# CPU_TPIU register map
Vendor: Texas Instruments
Peripheral module from a debugger description file (folder CC26x4).
Registers are 32-bit, read-only, reset 0x0 unless marked. A register's access mark holds for its fields unless they carry their own. Offsets are as the file gives them; lines under a group give offsets from that group; [hi:lo] are bit positions; {n}, {i} and the like mark numbered series; 'fields as' and 'values as' point back to an identical list; <NAME> marks a mode.

## CPU_TPIU — Cortex-M's Trace Port Interface Unit (TPIU)
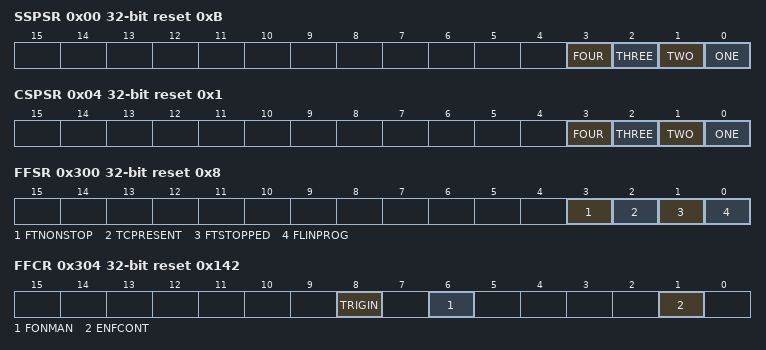
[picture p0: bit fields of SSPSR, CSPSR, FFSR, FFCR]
0x00 SSPSR reset 0xB — Supported Sync Port Sizes This register represents a single port size that is supported on the device, that is, 4, 2 or 1. This is to ensure that tools do not attempt to select a port width that an attached TPA cannot capture.
  [3] FOUR — 4-bit port size support 0x0: Not supported 0x1: Supported
  [2] THREE — 3-bit port size support 0x0: Not supported 0x1: Supported
  [1] TWO — 2-bit port size support 0x0: Not supported 0x1: Supported
  [0] ONE — 1-bit port size support 0x0: Not supported 0x1: Supported
0x04 CSPSR rw reset 0x1 — Current Sync Port Size This register has the same format as SSPSR but only one bit can be set, and all others must be zero. Writing values with more than one bit set, or setting a bit that is not indicated as supported can cause Unpredictable behavior. On reset this defaults to the smallest possible port size, 1 bit.
  [3] FOUR — 4-bit port enable Writing values with more than one bit set in CSPSR, or setting a bit that is not indicated as supported in SSPSR can cause Unpredictable behavior.
  [2] THREE — 3-bit port enable Writing values with more than one bit set in CSPSR, or setting a bit that is not indicated as supported in SSPSR can cause Unpredictable behavior.
  [1] TWO — 2-bit port enable Writing values with more than one bit set in CSPSR, or setting a bit that is not indicated as supported in SSPSR can cause Unpredictable behavior.
  [0] ONE — 1-bit port enable Writing values with more than one bit set in CSPSR, or setting a bit that is not indicated as supported in SSPSR can cause Unpredictable behavior.
0x10 ACPR rw — Async Clock Prescaler This register scales the baud rate of the asynchronous output.
  [12:0] PRESCALER — Divisor for input trace clock is (PRESCALER + 1).
0xF0 SPPR rw reset 0x1 — Selected Pin Protocol This register selects the protocol to be used for trace output. Note: If this register is changed while trace data is being output, data corruption occurs.
  [1:0] PROTOCOL — Trace output protocol
    2=SWO_NRZ (SerialWire Output (NRZ)); 1=SWO_MANCHESTER (SerialWire Output (Manchester). This is the reset value.); 0=TRACEPORT (TracePort mode)
0x300 FFSR reset 0x8 — Formatter and Flush Status
  [3] FTNONSTOP — 0: Formatter can be stopped 1: Formatter cannot be stopped
  [2] TCPRESENT — This field always reads as zero
  [1] FTSTOPPED — This field always reads as zero
  [0] FLINPROG — Read only. Flush in progress. Value can be: 0x0 When all the data received, before the flush is acknowledged, has been output on the trace port 0x1 When a flush is initiated.
0x304 FFCR rw reset 0x142 — Formatter and Flush Control When one of the two single wire output (SWO) modes is selected, ENFCONT enables the formatter to be bypassed. If the formatter is bypassed, only the ITM/DWT trace source (ATDATA2) passes through. The TPIU accepts and discards data that is presented on the ETM port (ATDATA1). This function is intended to be used when it is necessary to connect a device containing an ETM to a trace capture device that is only able to capture Serial Wire Output (SWO) data. Enabling or disabling the formatter causes momentary data corruption. Note: If the selected pin protocol register (SPPR.PROTOCOL) is set to 0x00 (TracePort mode), this register always reads 0x102, because the formatter is automatically enabled. If one of the serial wire modes is then selected, the register reverts to its previously programmed value.
  [8] TRIGIN — Indicates that triggers are inserted when a trigger pin is asserted.
  [6] FONMAN — Flush on manual. Value can be: 0x0 When the flush completes. Set to 0 on a reset of the TPIU. 0x1 Generates a flush.
  [1] ENFCONT — Enable continuous formatting: 0: Continuous formatting disabled 1: Continuous formatting enabled
0x308 PSCR access per field — Formatter Synchronization Counter
  [4:0] PSCOUNT rw — Periodic Synchronization Count. Determines the reload value of the Periodic Synchronization Counter. The reload value takes effect the next time the counter reaches zero. Reads from this register return the reload value programmed into this register 0b00000 Synchronization disabled. 0b00111 128 bytes. 0b01000 256 bytes. 0b11111 2^31 bytes.
0xFA0 CLAIMMASK reset 0xF — Claim Tag Mask
  [31:0] CLAIMMASK — This register forms one half of the Claim Tag value. When reading this register returns the number of bits that can be set (each bit is considered separately): 0: This claim tag bit is not implemented 1: This claim tag bit is implemented The behavior when writing to this register is described in CLAIMSET.
0xFA0 CLAIMSET wo reset 0xF — Claim Tag Set
  [31:0] CLAIMSET — This register forms one half of the Claim Tag value. Writing to this location allows individual bits to be set (each bit is considered separately): 0: No effect 1: Set this bit in the claim tag The behavior when reading from this location is described in CLAIMMASK.
0xFA4 CLAIMTAG — Current Claim Tag
  [31:0] CLAIMTAG — This register forms one half of the Claim Tag value. Reading this register returns the current Claim Tag value. Reading CLAIMMASK determines how many bits from this register must be used. The behavior when writing to this register is described in CLAIMCLR.
0xFA4 CLAIMCLR wo — Claim Tag Clear
  [31:0] CLAIMCLR — This register forms one half of the Claim Tag value. Writing to this location enables individual bits to be cleared (each bit is considered separately): 0: No effect 1: Clear this bit in the claim tag. The behavior when reading from this location is described in CLAIMTAG.
0xFC8 DEVID reset 0xCA0 — Device ID
  [31:0] DEVID — This field returns: 0xCA1 if there is an ETM present. 0xCA0 if there is no ETM present.
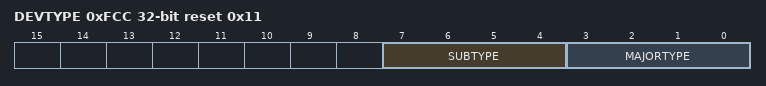
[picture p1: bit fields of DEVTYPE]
0xFCC DEVTYPE reset 0x11 — The Device Type Identification
  [7:4] SUBTYPE — Identifies the classification of the debug component
  [3:0] MAJORTYPE — Indicates this device is a trace sink and specifically a TPIU
